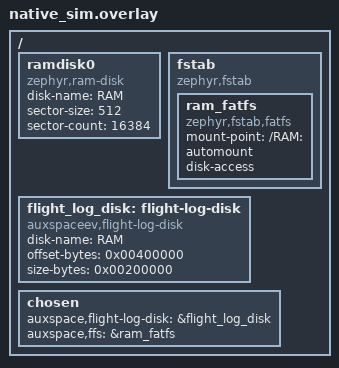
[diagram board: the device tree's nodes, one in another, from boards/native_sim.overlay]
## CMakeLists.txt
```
# Copyright (c) 2026 Auxspace e.V.
# SPDX-License-Identifier: Apache-2.0

cmake_minimum_required(VERSION 3.20.0)
find_package(Zephyr REQUIRED HINTS $ENV{ZEPHYR_BASE})
project(aurora_lib_data_disk_auto_mkfs_test)

FILE(GLOB app_sources src/*.c)
target_sources(app PRIVATE ${app_sources})
```

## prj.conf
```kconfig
CONFIG_ZTEST=y

# Data logger with the disk-backed binary backend and the auto-mkfs guard
# under test.
CONFIG_DATA_LOGGER=y
CONFIG_DATA_LOGGER_BIN=y
CONFIG_DATA_LOGGER_BIN_BACKEND_DISK=y
CONFIG_DATA_LOGGER_DISK_AUTO_MKFS=y

# RAM disk + FatFS volume, both auto-mounted via the DTS overlay before
# any test runs.  The auto-mkfs hook (SYS_INIT, APPLICATION level) runs
# after the fstab automount and is what reformats the blank disk.
CONFIG_DISK_DRIVERS=y
CONFIG_FILE_SYSTEM=y
CONFIG_FAT_FILESYSTEM_ELM=y
CONFIG_FS_FATFS_LFN=y
CONFIG_FS_FATFS_FSTAB_AUTOMOUNT=y

# Heap for FatFs MKFS scratch buffers.
CONFIG_HEAP_MEM_POOL_SIZE=8192
```

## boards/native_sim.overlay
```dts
/*
 * Copyright (c) 2026 Auxspace e.V.
 * SPDX-License-Identifier: Apache-2.0
 *
 * Minimal disk layout for the auto-mkfs test:
 *
 *   - 8 MiB RAM disk named "RAM"
 *   - FatFS volume mounted at /RAM: via fstab automount
 *   - flight-log raw region at offset 4 MiB, size 2 MiB
 *
 * Sized just large enough that part_start lands on the 1 MiB-aligned
 * sector (PART1_ALIGNED_LBA = 2048) inside the auto-format module, so
 * the FAT partition occupies sectors [2048, 8192) and the raw region
 * begins immediately after at sector 8192 (= 4 MiB).  The trailing
 * 2 MiB of the disk is unused and gives the raw region headroom.
 */

/ {
	ramdisk0 {
		compatible = "zephyr,ram-disk";
		disk-name = "RAM";
		sector-size = <512>;
		sector-count = <16384>;	/* 8 MiB */
	};

	fstab {
		compatible = "zephyr,fstab";

		ram_fatfs: ram_fatfs {
			compatible = "zephyr,fstab,fatfs";
			mount-point = "/RAM:";
			automount;
			disk-access;
		};
	};

	flight_log_disk: flight-log-disk {
		compatible = "auxspaceev,flight-log-disk";
		disk-name = "RAM";
		offset-bytes = <0x00400000>;	/* 4 MiB */
		size-bytes   = <0x00200000>;	/* 2 MiB */
	};

	chosen {
		auxspace,flight-log-disk = &flight_log_disk;
		auxspace,ffs = &ram_fatfs;
	};
};
```

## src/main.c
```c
/**
 * @file main.c
 * @brief Unit tests for the disk-backed flight-log auto-mkfs guard.
 *
 * The auto-mkfs module (aurora/lib/data/flight_log_disk_auto_format.c)
 * coexists a FAT volume and a raw flight-log region on a single
 * disk-access device.  At boot, after Zephyr's fstab has tried to
 * automount the FAT volume, the module reads the first sector of the
 * raw region, looks for the AURORA flight-frame magic, and either
 * preserves the disk untouched or rewrites the MBR plus reformats the
 * FAT partition so that the raw region structurally lies outside any
 * filesystem.
 *
 * Three suites cover the arms of that guard:
 *
 *  1. **disk_auto_mkfs_blank** — exercises the format-on-mismatch path.
 *     The simulator brings up a blank RAM disk, Zephyr's automount fails
 *     (no FAT yet), the auto-mkfs SYS_INIT hook then writes a fresh MBR
 *     and calls fs_mkfs(), and the FatFS volume is mounted before the
 *     first test runs.  The suite asserts that the volume is mounted
 *     and that ordinary file I/O succeeds, end to end.
 *
 *  2. **disk_auto_mkfs_preserve** — exercises the preservation path.
 *     The test seeds the configured raw-region offset with the AURORA
 *     flight-frame magic and re-invokes the auto-format entry point
 *     directly to mimic a reboot from a populated card.  With the magic
 *     present AND the FAT already mounted, the guard must short-circuit,
 *     leave the raw bytes intact, and leave the FAT volume mounted.
 *
 *  3. **disk_auto_mkfs_corrupt** — regression test for a field failure
 *     where a corrupt FAT plus a valid flight log left the card neither
 *     reformatted nor mounted (the magic was wrongly treated as the sole
 *     gate).  The test seeds the magic, destroys the FAT metadata, and
 *     re-invokes: the guard must rebuild the FAT (restoring disk logging)
 *     while the raw flight region survives untouched.
 *
 * Copyright (c) 2026 Auxspace e.V.
 *
 * SPDX-License-Identifier: Apache-2.0
 */

#include <string.h>
#include <errno.h>

#include <zephyr/ztest.h>
#include <zephyr/devicetree.h>
#include <zephyr/fs/fs.h>
#include <zephyr/storage/disk_access.h>

#include <aurora/lib/data_logger.h>

#define DISK_NODE         DT_CHOSEN(auxspace_flight_log_disk)
#define DISK_NAME         DT_PROP(DISK_NODE, disk_name)
#define DISK_OFFSET_BYTES                                                   \
	(((uint64_t)DT_PROP_BY_IDX(DISK_NODE, offset_bytes, 0) << 32) |     \
	 (uint64_t)DT_PROP_BY_IDX(DISK_NODE, offset_bytes, 1))

#define FS_MOUNT_POINT    "/RAM:"
#define SENTINEL_PATH     FS_MOUNT_POINT "/sentinel.txt"
#define SENTINEL_PAYLOAD  "auto-mkfs-ok"

/* Re-entry point exported by the auto-mkfs module.  Production callers
 * use the SYS_INIT hook; tests call this directly to simulate a reboot.
 */
extern int flight_log_disk_auto_format(void);

/* fstab mount entry (same one the module manages) so the corrupt-FAT suite
 * can unmount the volume before mangling its on-disk metadata.
 */
#define FS_NODE  DT_CHOSEN(auxspace_ffs)
FS_FSTAB_DECLARE_ENTRY(FS_NODE);

/* One-sector scratch buffer for raw disk_access_read/write probes. */
static uint8_t scratch[512];

static uint32_t sector_size_bytes(void)
{
	uint32_t sz = 0;

	zassert_ok(disk_access_ioctl(DISK_NAME,
				     DISK_IOCTL_GET_SECTOR_SIZE, &sz), NULL);
	zassert_true(sz != 0 && sz <= sizeof(scratch),
		     "Unexpected sector size %u (scratch is %zu bytes)",
		     sz, sizeof(scratch));
	return sz;
}

/* ========================================================================== */
/*  Suite 1: format-on-mismatch (blank disk → mounted FAT)                    */
/* ========================================================================== */

ZTEST_SUITE(disk_auto_mkfs_blank, NULL, NULL, NULL, NULL, NULL);

/**
 * @brief A blank RAM disk is reformatted at SYS_INIT and the FAT volume
 *        is mounted before the first test executes.
 *
 * The presence of a usable f_blocks count on @ref FS_MOUNT_POINT is the
 * primary signal: it means fstab automount (which fails on a blank disk)
 * was followed by the auto-mkfs hook reformatting and remounting the
 * volume.
 */
ZTEST(disk_auto_mkfs_blank, test_blank_disk_mounted_after_boot)
{
	struct fs_statvfs vfs;

	zassert_ok(fs_statvfs(FS_MOUNT_POINT, &vfs),
		   "auto-mkfs at SYS_INIT must leave " FS_MOUNT_POINT
		   " mounted");
	zassert_true(vfs.f_blocks > 0,
		     "FAT volume must report a non-zero block count");
	zassert_true(flight_log_online(),
		     "bring-up must latch the flight log online on a "
		     "healthy disk (arming interlock)");
}

/**
 * @brief The freshly formatted FAT volume accepts ordinary file I/O.
 *
 * Writes a small sentinel file, closes it, reopens it for read, and
 * verifies the payload round-trips byte-for-byte.  This catches cases
 * where fs_mkfs() succeeded but produced a structurally broken volume
 * that f_open / f_write would later reject.
 */
ZTEST(disk_auto_mkfs_blank, test_blank_disk_filesystem_writable)
{
	struct fs_file_t f;
	char readback[sizeof(SENTINEL_PAYLOAD)] = {0};

	(void)fs_unlink(SENTINEL_PATH);

	fs_file_t_init(&f);
	zassert_ok(fs_open(&f, SENTINEL_PATH,
			   FS_O_CREATE | FS_O_WRITE), NULL);
	zassert_equal(fs_write(&f, SENTINEL_PAYLOAD,
			       sizeof(SENTINEL_PAYLOAD) - 1),
		      (ssize_t)sizeof(SENTINEL_PAYLOAD) - 1, NULL);
	zassert_ok(fs_close(&f), NULL);

	fs_file_t_init(&f);
	zassert_ok(fs_open(&f, SENTINEL_PATH, FS_O_READ), NULL);
	zassert_equal(fs_read(&f, readback, sizeof(readback) - 1),
		      (ssize_t)sizeof(SENTINEL_PAYLOAD) - 1, NULL);
	zassert_ok(fs_close(&f), NULL);

	zassert_str_equal(readback, SENTINEL_PAYLOAD,
			  "Sentinel payload must round-trip through the "
			  "freshly formatted FAT volume");
}

/* ========================================================================== */
/*  Suite 2: preservation (magic at offset → no reformat across "reboot")     */
/* ========================================================================== */

ZTEST_SUITE(disk_auto_mkfs_preserve, NULL, NULL, NULL, NULL, NULL);

/**
 * @brief A re-invocation of the auto-format entry point with the AURORA
 *        flight-frame magic present at the raw-region offset must leave
 *        the magic intact and leave the FAT volume mounted.
 *
 * The test mimics a reboot from a populated card: it writes the magic
 * into the first sector of the raw region (which lies outside the FAT
 * partition by construction), calls @ref flight_log_disk_auto_format
 * again, and asserts both that the magic survives the call and that the
 * mounted filesystem is still usable.  This is the only path that
 * preserves recorded flight data on the next boot, so it is intentionally
 * the strictest of the two suites: any silent reformat here would
 * destroy a flight log on a real card.
 */
ZTEST(disk_auto_mkfs_preserve, test_magic_survives_reentry)
{
	uint32_t sector_size = sector_size_bytes();
	uint32_t off_sec = (uint32_t)(DISK_OFFSET_BYTES / sector_size);

	memset(scratch, 0, sector_size);
	memcpy(scratch, AURORA_BIN_FRAME_MAGIC,
	       sizeof(AURORA_BIN_FRAME_MAGIC) - 1);
	zassert_ok(disk_access_write(DISK_NAME, scratch, off_sec, 1),
		   "seeding the magic at sector %u must succeed", off_sec);

	zassert_ok(flight_log_disk_auto_format(),
		   "auto-format re-entry must return success when magic "
		   "is present");

	memset(scratch, 0, sector_size);
	zassert_ok(disk_access_read(DISK_NAME, scratch, off_sec, 1), NULL);
	zassert_mem_equal(scratch, AURORA_BIN_FRAME_MAGIC,
			  sizeof(AURORA_BIN_FRAME_MAGIC) - 1,
			  "Flight magic must survive an auto-format re-entry");

	struct fs_statvfs vfs;

	zassert_ok(fs_statvfs(FS_MOUNT_POINT, &vfs),
		   FS_MOUNT_POINT " must remain mounted across the "
		   "preservation re-entry");
}

/* ========================================================================== */
/*  Suite 3: corrupt FAT + flight data (rebuild FAT, preserve raw region)     */
/* ========================================================================== */

ZTEST_SUITE(disk_auto_mkfs_corrupt, NULL, NULL, NULL, NULL, NULL);

/**
 * @brief A corrupt/unmountable FAT that still carries a valid flight log
 *        must be rebuilt: the raw region survives and the volume comes
 *        back mounted and usable.
 *
 * Regression test for the field failure where a corrupt filesystem plus a
 * recovered flight log left the card neither reformatted nor mounted, the
 * flight-log magic was treated as the sole gate, so a broken FAT with data
 * present short-circuited the guard and disk logging stayed dead.
 *
 * The test seeds the magic at the raw-region offset, unmounts the volume,
 * then destroys the FAT metadata (the MBR at sector 0 and the partition-1
 * boot sector at PART1_ALIGNED_LBA) so it can no longer be mounted.  It
 * re-invokes the guard and asserts the magic survived and the FAT is
 * mounted with a non-zero block count.
 */
ZTEST(disk_auto_mkfs_corrupt, test_corrupt_fat_with_flight_data_rebuilds)
{
	uint32_t sector_size = sector_size_bytes();
	uint32_t off_sec = (uint32_t)(DISK_OFFSET_BYTES / sector_size);
	struct fs_statvfs vfs;

	/* Seed a valid flight log in the raw region. */
	memset(scratch, 0, sector_size);
	memcpy(scratch, AURORA_BIN_FRAME_MAGIC,
	       sizeof(AURORA_BIN_FRAME_MAGIC) - 1);
	zassert_ok(disk_access_write(DISK_NAME, scratch, off_sec, 1),
		   "seeding the magic at sector %u must succeed", off_sec);

	/* Take the volume down before mangling its on-disk metadata. */
	if (fs_statvfs(FS_MOUNT_POINT, &vfs) == 0) {
		zassert_ok(fs_unmount(&FS_FSTAB_ENTRY(FS_NODE)), NULL);
	}

	/* Destroy the FAT: wipe the MBR (sector 0) and the partition-1 boot
	 * sector (PART1_ALIGNED_LBA = 2048, where fs_mkfs put the VBR for this
	 * geometry) so f_mount can find no filesystem.
	 */
	memset(scratch, 0xA5, sector_size);
	zassert_ok(disk_access_write(DISK_NAME, scratch, 0, 1),
		   "wiping the MBR must succeed");
	zassert_ok(disk_access_write(DISK_NAME, scratch, 2048, 1),
		   "wiping the partition-1 boot sector must succeed");

	/* Re-invoke: the guard must rebuild the FAT rather than preserve. */
	zassert_ok(flight_log_disk_auto_format(),
		   "auto-format must rebuild a corrupt FAT even with flight "
		   "data present");

	/* The recorded flight data must survive the rebuild untouched. */
	memset(scratch, 0, sector_size);
	zassert_ok(disk_access_read(DISK_NAME, scratch, off_sec, 1), NULL);
	zassert_mem_equal(scratch, AURORA_BIN_FRAME_MAGIC,
			  sizeof(AURORA_BIN_FRAME_MAGIC) - 1,
			  "Flight magic must survive a corrupt-FAT rebuild");

	/* Disk logging is restored: the volume is mounted and usable. */
	zassert_ok(fs_statvfs(FS_MOUNT_POINT, &vfs),
		   FS_MOUNT_POINT " must be mounted after the rebuild");
	zassert_true(vfs.f_blocks > 0,
		     "Rebuilt FAT volume must report a non-zero block count");
}
```
